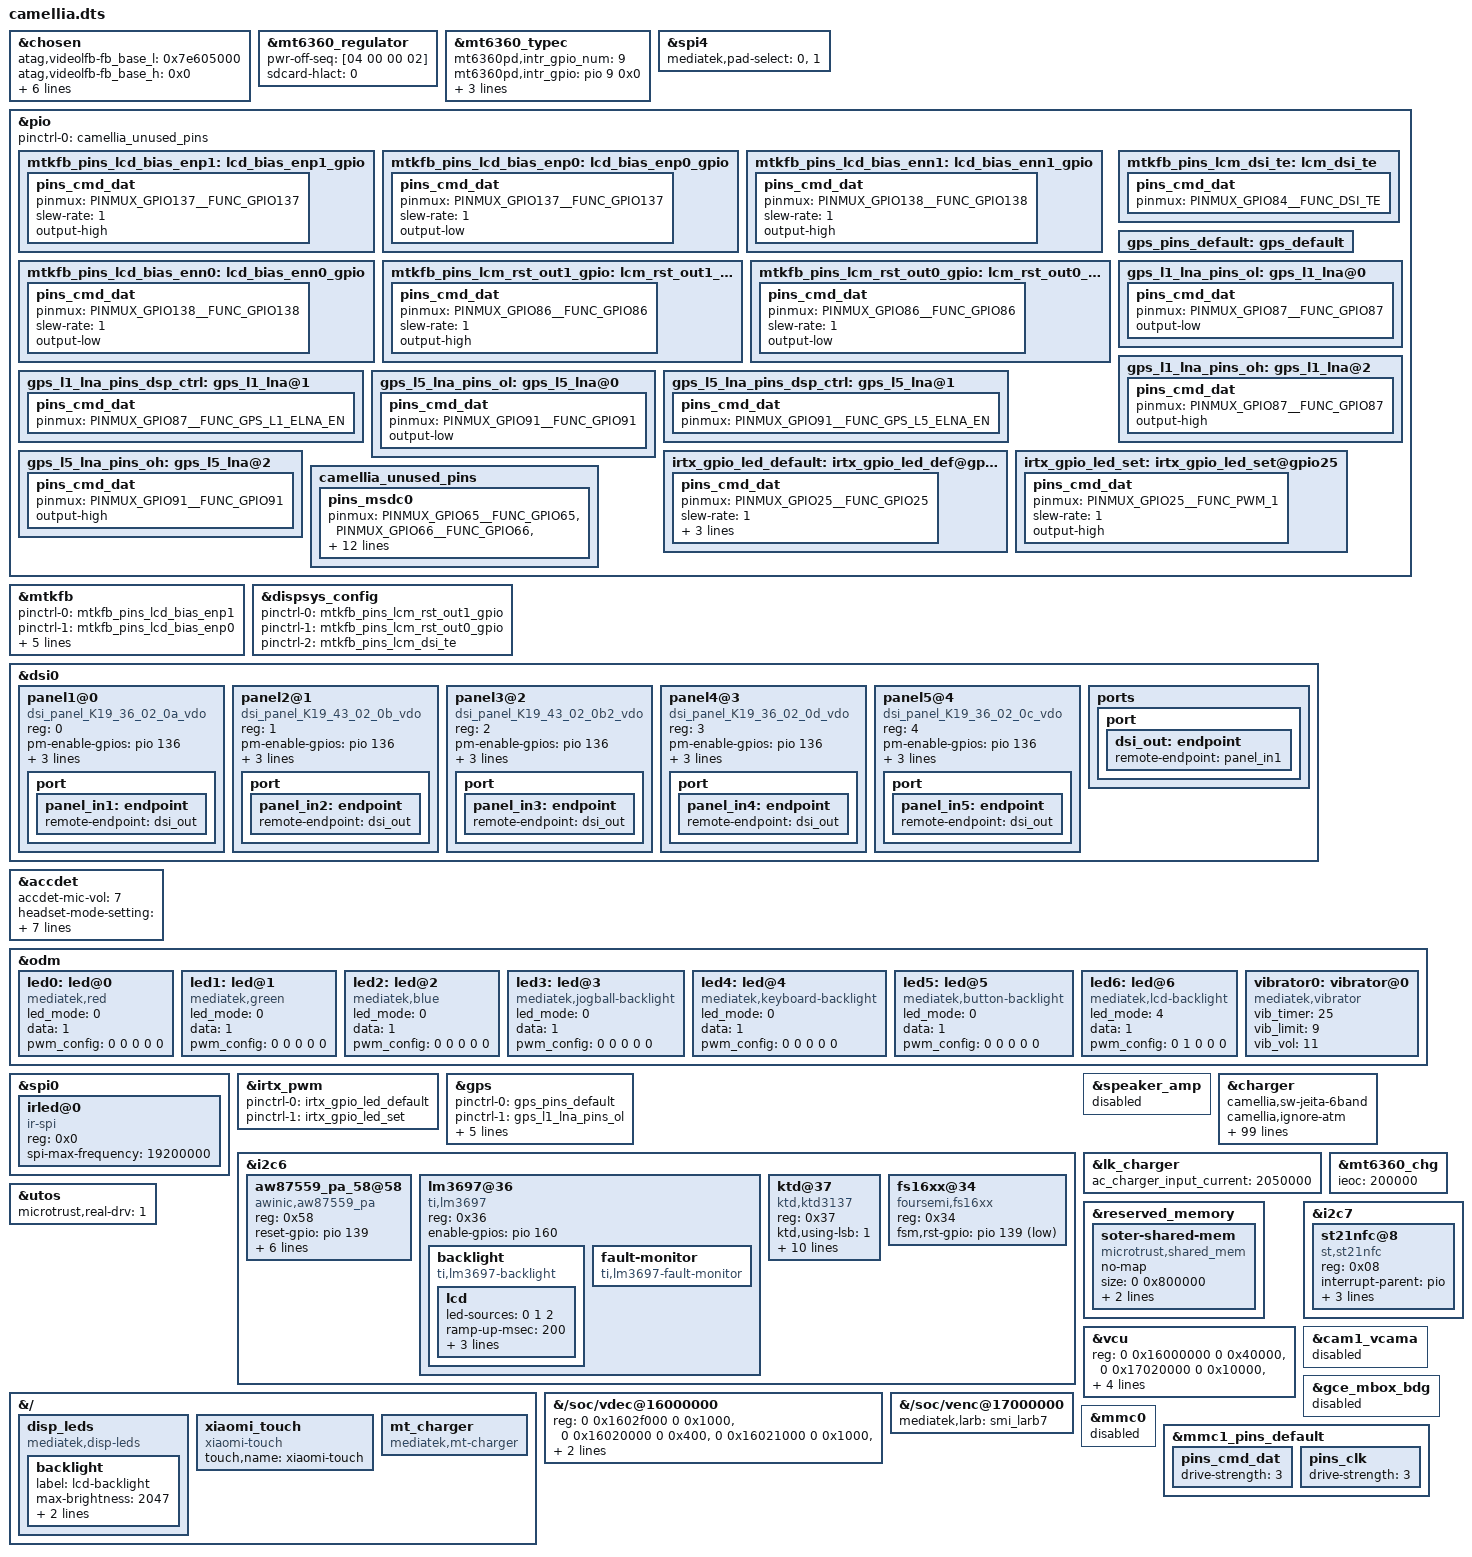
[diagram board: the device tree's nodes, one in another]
/*
 * Mediatek's mt6833 SoC device tree source
 *
 * Copyright (C) 2016 MediaTek Inc.
 *
 * This program is free software; you can redistribute it and/or modify
 * it under the terms of the GNU General Public License version 2 as
 * published by the Free Software Foundation.
 *
 * This program is distributed in the hope that it will be useful,
 * but WITHOUT ANY WARRANTY; without even the implied warranty of
 * MERCHANTABILITY or FITNESS FOR A PARTICULAR PURPOSE.
 * See http://www.gnu.org/licenses/gpl-2.0.html for more details.
 */
/dts-v1/;
/plugin/;
#include <dt-bindings/interrupt-controller/irq.h>
#include <dt-bindings/interrupt-controller/arm-gic.h>
#ifndef CONFIG_FPGA_EARLY_PORTING
#include <dt-bindings/pinctrl/mt6833-pinfunc.h>
#endif

/* chosen */
&chosen {
	atag,videolfb-fb_base_l = <0x7e605000>;
	atag,videolfb-fb_base_h = <0x0>;
	atag,videolfb-islcmfound = <1>;
	atag,videolfb-islcm_inited = <0>;
	atag,videolfb-fps= <6000>;
	atag,videolfb-vramSize= <0x1be0000>;
	atag,videolfb-lcmname=
		"nt36672c_fhdp_dsi_vdo_90hz_tianma_lcm_drv";
};

/*
 * camellia MT6360 settings in the 6.6 binding (4.14: &mt6360_ldo/_pmu/_pmic):
 * - main IRQ: GPIO10, already the 6.6 base (mt6360@34 interrupts = <&pio 10 ...>)
 * - power-off sequence [04 00 00 02]
 * - SD card detect: low level = card removed (sdcard-hlact 0; the 6.6 driver
 *   defaults to 1, which would invert microSD detection)
 */
&mt6360_regulator {
	pwr-off-seq = [04 00 00 02];
	sdcard-hlact = <0>;
};


/* BSP.Charge - 2020.11.02 - modify typec interrupt */
&mt6360_typec {
	mt6360pd,intr_gpio_num = <9>; /* direct defined GPIO num */
	mt6360pd,intr_gpio = <&pio 9 0x0>;
	/* camellia 6.6: the driver reads the dash names first, and the 6.6 base
	 * sets them to the reference board's GPIO11; camellia's TCPC IRQ is GPIO9 */
	mt6360pd,intr-gpio-num = <9>;
	mt6360pd,intr-gpio = <&pio 9 0x0>;
	/* camellia 4.14: role_def 5 (Try.SNK). The 6.6 base's Try.SRC makes a
	 * PC's DRP port see the phone as a source first, so USB device mode and
	 * BC1.2 only come up if the PC happens to swap roles back */
	mt-tcpc,role-def = <5>;
};

/* camellia 4.14: touch is NT36672C on CS0 / pad 0 or FT8722 on CS1 / pad 1
 * (by panel); spi-mt65xx gives one chip select per pad-select entry */
&spi4 {
	mediatek,pad-select = <0>, <1>;
};

#ifndef CONFIG_FPGA_EARLY_PORTING
&pio {
	mtkfb_pins_lcd_bias_enp1: lcd_bias_enp1_gpio {
		pins_cmd_dat {
			pinmux = <PINMUX_GPIO137__FUNC_GPIO137>;
			slew-rate = <1>;
			output-high;
		};
	};

	mtkfb_pins_lcd_bias_enp0: lcd_bias_enp0_gpio {
		pins_cmd_dat {
			pinmux = <PINMUX_GPIO137__FUNC_GPIO137>;
			slew-rate = <1>;
			output-low;
		};
	};

	mtkfb_pins_lcd_bias_enn1: lcd_bias_enn1_gpio {
		pins_cmd_dat {
			pinmux = <PINMUX_GPIO138__FUNC_GPIO138>;
			slew-rate = <1>;
			output-high;
		};
	};

	mtkfb_pins_lcd_bias_enn0: lcd_bias_enn0_gpio {
		pins_cmd_dat {
			pinmux = <PINMUX_GPIO138__FUNC_GPIO138>;
			slew-rate = <1>;
			output-low;
		};
	};

	mtkfb_pins_lcm_rst_out1_gpio: lcm_rst_out1_gpio {
		pins_cmd_dat {
			pinmux = <PINMUX_GPIO86__FUNC_GPIO86>;
			slew-rate = <1>;
			output-high;
		};
	};

	mtkfb_pins_lcm_rst_out0_gpio: lcm_rst_out0_gpio {
		pins_cmd_dat {
			pinmux = <PINMUX_GPIO86__FUNC_GPIO86>;
			slew-rate = <1>;
			output-low;
		};
	};
	mtkfb_pins_lcm_dsi_te: lcm_dsi_te {
		pins_cmd_dat {
			pinmux = <PINMUX_GPIO84__FUNC_DSI_TE>;
		};
	};
};

&mtkfb {
	pinctrl-names = "lcd_bias_enp1_gpio", "lcd_bias_enp0_gpio",
		"lcd_bias_enn1_gpio", "lcd_bias_enn0_gpio",
		"lcm_rst_out1_gpio", "lcm_rst_out0_gpio",
		"mode_te_te";
	pinctrl-0 = <&mtkfb_pins_lcd_bias_enp1>;
	pinctrl-1 = <&mtkfb_pins_lcd_bias_enp0>;
	pinctrl-2 = <&mtkfb_pins_lcd_bias_enn1>;
	pinctrl-3 = <&mtkfb_pins_lcd_bias_enn0>;
	pinctrl-4 = <&mtkfb_pins_lcm_rst_out1_gpio>;
	pinctrl-5 = <&mtkfb_pins_lcm_rst_out0_gpio>;
	pinctrl-6 = <&mtkfb_pins_lcm_dsi_te>;
	status = "okay";
};
&dispsys_config {
	pinctrl-names =
		"lcm_rst_out1_gpio", "lcm_rst_out0_gpio",
		"mode_te_te";
	pinctrl-0 = <&mtkfb_pins_lcm_rst_out1_gpio>;
	pinctrl-1 = <&mtkfb_pins_lcm_rst_out0_gpio>;
	pinctrl-2 = <&mtkfb_pins_lcm_dsi_te>;
	status = "okay";
};

&dsi0 {
	status = "okay";
	#address-cells = <1>;
	#size-cells = <0>;
	/* BSP.lcm - 2020.11.19 - start */
	panel1@0 {
		compatible = "dsi_panel_K19_36_02_0a_vdo";
		reg = <0>;
		pm-enable-gpios = <&pio 136 0>;
		reset-gpios = <&pio 86 0>;
		pwm-gpios = <&pio 85 0>;
		bias-gpios = <&pio 137 0>,
			<&pio 138 0>;
		pinctrl-names = "default";
		port {
			panel_in1: endpoint {
				remote-endpoint = <&dsi_out>;
			};
		};
	};
	panel2@1 {
		compatible = "dsi_panel_K19_43_02_0b_vdo";
		reg = <1>;
		pm-enable-gpios = <&pio 136 0>;
		reset-gpios = <&pio 86 0>;
		pwm-gpios = <&pio 85 0>;
		bias-gpios = <&pio 137 0>,
			<&pio 138 0>;
		pinctrl-names = "default";
		port {
			panel_in2: endpoint {
				remote-endpoint = <&dsi_out>;
			};
		};
	};
	panel3@2 {
		compatible = "dsi_panel_K19_43_02_0b2_vdo";
		reg = <2>;
		pm-enable-gpios = <&pio 136 0>;
		reset-gpios = <&pio 86 0>;
		pwm-gpios = <&pio 85 0>;
		bias-gpios = <&pio 137 0>,
			<&pio 138 0>;
		pinctrl-names = "default";
		port {
			panel_in3: endpoint {
				remote-endpoint = <&dsi_out>;
			};
		};
	};
	panel4@3 {
		compatible = "dsi_panel_K19_36_02_0d_vdo";
		reg = <3>;
		pm-enable-gpios = <&pio 136 0>;
		reset-gpios = <&pio 86 0>;
		pwm-gpios = <&pio 85 0>;
		bias-gpios = <&pio 137 0>,
			<&pio 138 0>;
		pinctrl-names = "default";
		port {
			panel_in4: endpoint {
				remote-endpoint = <&dsi_out>;
			};
		};
	};
	panel5@4 {
		compatible = "dsi_panel_K19_36_02_0c_vdo";
		reg = <4>;
		pm-enable-gpios = <&pio 136 0>;
		reset-gpios = <&pio 86 0>;
		pwm-gpios = <&pio 85 0>;
		bias-gpios = <&pio 137 0>,
			<&pio 138 0>;
		pinctrl-names = "default";
		port {
			panel_in5: endpoint {
				remote-endpoint = <&dsi_out>;
			};
		};
	};
	ports {
		port {
			dsi_out: endpoint {
				remote-endpoint = <&panel_in1>;
			};
		};
	};
};
#endif

/*BSP.Touch - Change dtsi file - 2020.11.18 - Start*/
/*#include "mediatek/cust_mt6833_touch_1080x2300.dtsi"*/
#include "mediatek/cust_mt6833_touch_1080x2400.dtsi"
/*BSP.Touch - Change dtsi file - 2020.11.18 - End*/
/* accdet start */
&accdet {
	/* accdet micbias voltage: 0x09:2.85v 0x08:2.8v 0x07,
	 * 2.7v;0x05,2.5v;0x02,1.9v
	 */
	/* BSP.audio - 2020.11.12 - modify to micbias of headphone start */
	accdet-mic-vol = <7>;
	/* BSP.audio - 2020.11.12 - modify to micbias of headphone end */
	/* accdet pwm_width, pwm_thresh, fall_delay, rise_delay
	 * debounce0, debounce1, debounce3, debounce4
	 * eint pwm_width, eint pwm_thresh
	 * eint deb(debounce0, debounce1, debounce2, debounce3), inv_debounce
	 */
	headset-mode-setting = <0x500 0x500 1 0x1f0
				0x800 0x800 0x20 0x44
				0x4 0x1
				0x5 0x3 0x3 0x5 0xe>;
	accdet-plugout-debounce = <1>;
	/*1:ACC mode, 2:low cost without in bias, 6:low cost with in bias*/
	accdet-mic-mode = <2>;
	/*0--MD_MAX--UP_MAX--DW_MAX*/
	headset-three-key-threshold = <0 80 220 400>;
	headset-three-key-threshold-CDD = <0 121 192 600>;
	/*0--MD_MAX--VOICE_MAX--UP_MAX--DW_MAX*/
	headset-four-key-threshold = <0 58 121 192 400>;

	/* select VTH to 2v and 500k, use internal resitance */
	eint_use_ext_res = <0>;
	status = "okay";
};
/* accdet end */

&odm {
	led0:led@0 {
		compatible = "mediatek,red";
		led_mode = <0>;
		data = <1>;
		pwm_config = <0 0 0 0 0>;
	};
	led1:led@1 {
		compatible = "mediatek,green";
		led_mode = <0>;
		data = <1>;
		pwm_config = <0 0 0 0 0>;
	};
	led2:led@2 {
		compatible = "mediatek,blue";
		led_mode = <0>;
		data = <1>;
		pwm_config = <0 0 0 0 0>;
	};
	led3:led@3 {
		compatible = "mediatek,jogball-backlight";
		led_mode = <0>;
		data = <1>;
		pwm_config = <0 0 0 0 0>;
	};
	led4:led@4 {
		compatible = "mediatek,keyboard-backlight";
		led_mode = <0>;
		data = <1>;
		pwm_config = <0 0 0 0 0>;
	};
	led5:led@5 {
		compatible = "mediatek,button-backlight";
		led_mode = <0>;
		data = <1>;
		pwm_config = <0 0 0 0 0>;
	};
	led6:led@6 {
		compatible = "mediatek,lcd-backlight";
		/* BSP.LCM - 2020.11.25 - modify to set brightness */
		led_mode = <4>;
		data = <1>;
		pwm_config = <0 1 0 0 0>;
	};
	vibrator0:vibrator@0 {
		compatible = "mediatek,vibrator";
		vib_timer = <25>;
		vib_limit = <9>;
	/* BSP.Charge - 2020.11.18 - Fixed the vibrator voltage */
		vib_vol= <11>;
	};
};
/* GPS GPIO standardization start */
&pio {
	gps_pins_default: gps_default {
	};

	gps_l1_lna_pins_ol: gps_l1_lna@0 {
		pins_cmd_dat {
			pinmux = <PINMUX_GPIO87__FUNC_GPIO87>;
			output-low;
		};
	};
	gps_l1_lna_pins_dsp_ctrl: gps_l1_lna@1 {
		pins_cmd_dat {
			pinmux = <PINMUX_GPIO87__FUNC_GPS_L1_ELNA_EN>;
		};
	};
	gps_l1_lna_pins_oh: gps_l1_lna@2 {
		pins_cmd_dat {
			pinmux = <PINMUX_GPIO87__FUNC_GPIO87>;
			output-high;
		};
	};

	gps_l5_lna_pins_ol: gps_l5_lna@0 {
		pins_cmd_dat {
			pinmux = <PINMUX_GPIO91__FUNC_GPIO91>;
			output-low;
		};
	};
	gps_l5_lna_pins_dsp_ctrl: gps_l5_lna@1 {
		pins_cmd_dat {
			pinmux = <PINMUX_GPIO91__FUNC_GPS_L5_ELNA_EN>;
		};
	};
	gps_l5_lna_pins_oh: gps_l5_lna@2 {
		pins_cmd_dat {
			pinmux = <PINMUX_GPIO91__FUNC_GPIO91>;
			output-high;
		};
	};
};
/*BSP.System - 2020.11.5 - add board id*/
#if 0 /* camellia 6.6 TODO: no Xiaomi board_id node/driver in 6.6 base; add node + driver */
&board_id {
	io-channels = <&auxadc 5>;
	io-channel-names = "board_id-channel";
	status = "okay";
};
#endif

&spi0 {
	status = "ok";
	irled@0 {
		compatible = "ir-spi";
		reg = <0x0>;
		//vdd-supply = <&pm8953_l8>; //vdd
		status = "ok";
		spi-max-frequency = <19200000>;
	};
};

&pio {
	/* IRTX GPIO Settings -Start */
	/* default: GPIO0, output, high */
	irtx_gpio_led_default:irtx_gpio_led_def@gpio25 {
		pins_cmd_dat {
			pinmux = <PINMUX_GPIO25__FUNC_GPIO25>;
			slew-rate = <1>;
			bias-disable;
			output-low;
			input-schmitt-enable = <0>;
		};
	};

	irtx_gpio_led_set:irtx_gpio_led_set@gpio25 {
		pins_cmd_dat {
			pinmux = <PINMUX_GPIO25__FUNC_PWM_1>;
			slew-rate = <1>;
			output-high;
		};
	};
}; /* IRTX GPIO Settings -End */

&irtx_pwm {
	pinctrl-names = "irtx_gpio_led_default", "irtx_gpio_led_set";
	pinctrl-0 = <&irtx_gpio_led_default>;
	pinctrl-1 = <&irtx_gpio_led_set>;
	status = "okay";
};

&gps {
	pinctrl-names = "default",
		"gps_l1_lna_disable",
		"gps_l1_lna_dsp_ctrl",
		"gps_l1_lna_enable",
		"gps_l5_lna_disable",
		"gps_l5_lna_dsp_ctrl",
		"gps_l5_lna_enable";
	pinctrl-0 = <&gps_pins_default>;
	pinctrl-1 = <&gps_l1_lna_pins_ol>;
	pinctrl-2 = <&gps_l1_lna_pins_dsp_ctrl>;
	pinctrl-3 = <&gps_l1_lna_pins_oh>;
	pinctrl-4 = <&gps_l5_lna_pins_ol>;
	pinctrl-5 = <&gps_l5_lna_pins_dsp_ctrl>;
	pinctrl-6 = <&gps_l5_lna_pins_oh>;
	status = "okay";
};
/* GPS GPIO standardization end */

/* BSP.Audio - 2020.11.2 - modify to bring up PA */
&i2c6 {
	aw87559_pa_58@58 {
		compatible = "awinic,aw87559_pa";
		reg = <0x58>;
		reset-gpio = <&pio 139 0>;
		monitor-flag = <1>;
		pa-channel = < 0 >;
		actflag-gain-array = < 0x00 0x08 0x08 0x08 0x00 >;
		gain-reg-addr = <0x06>;
		monitor-timer-val = <3000>;
		monitor-timer-count-max = <5>;
		status = "okay";
	};
};
/* end modify*/
/* BSP.LCM - 2020.11.14 - modify to set brightness */
&i2c6 {
	lm3697@36 {
		compatible = "ti,lm3697";
		reg = <0x36>;
		status = "okay";
		enable-gpios = <&pio 160 0>;
		backlight {
			compatible = "ti,lm3697-backlight";
			lcd {
				led-sources = <0 1 2>;
				ramp-up-msec = <200>;
				ramp-down-msec = <200>;
				pwm-period = <0>;
				default-brightness-level = <255>;
			};
		};
		fault-monitor {
			compatible = "ti,lm3697-fault-monitor";
		};
	};

	ktd@37 {
		compatible = "ktd,ktd3137";
		reg = <0x37>;
		status = "okay";
		/*ktd,pwm-mode; */
		ktd,using-lsb = <1>;
		ktd,pwm-frequency = <100>;
		ktd,bl-fscal-led = <0xA9>;/*default 21.8mA*/
		ktd,turn-on-ramp = <0>;
		ktd,turn-off-ramp = <0>;
		ktd,pwm-trans-dim = <0>;
		ktd,i2c-trans-dim = <0>;
		ktd,bl-channel = <2>;
		ktd,ovp-level = <32>; /*default 32v*/
		ktd,switching-frequency = <1000>; /*default 1000kHz*/
		ktd,inductor-current = <2600>; //default 2600mA
		//ktd,linear_ramp = <1>; /*default is exponential*/
		//ktd,linear_backlight = <1>; /*default is exponential*/
		};
};
/* end modify*/

/* camellia: the FS1815 below sits at 0x34; MTK's generic smart-PA node too */
&speaker_amp {
	status = "disabled";
};

/* BSP.Audio - 2020.11.11 - modify to bring up second PA */
&i2c6 {
	fs16xx@34 {
		compatible = "foursemi,fs16xx";
		reg = <0x34>;
		fsm,rst-gpio = <&pio 139 1>;
		status = "okay";
	};
};
/* end modify*/
#include "mediatek/cust_camellia_camera.dtsi"
#include <camellia/cust.dtsi>
#include "mediatek/cust_camellia_fingerprint.dtsi"

/*End of this file, DO NOT ADD ANYTHING HERE*/

/*
 * camellia charger settings: Xiaomi's 4.14 "mediatek,charger" node (camellian-t-oss
 * mt6833.dts). Phandle properties keep the 6.6 base values. camellia,sw-jeita-6band
 * enables Xiaomi's 6-band sw JEITA with per-band current limits (ported to 6.6).
 */
&charger {
	camellia,sw-jeita-6band;
	camellia,ignore-atm;
	/* camellia 4.14 used Xiaomi's "SwitchCharging2"; 6.6 has Basic/Pulse */
	algorithm_name = "Basic";
		/* BSP.Charge - 2020.12.02 - Eanble sw_jeita */
		enable_sw_jeita;
		/* enable_pe_plus; */
		/* enable_pe_2; */
		/* enable_pe_3; */
		/* enable_pe_4; */
		enable_type_c;
		power_path_support;
		enable_dynamic_mivr;

		/* common */
		battery_cv = <4350000>;
		/* BSP.Charge - 2021.01.11 - add ffc  parameters - start */
		enable_sw_ffc;
		ffc_cv_1 = <4440000>;
		ffc_cv_2 = <4430000>;
		ffc_cv_3 = <4420000>;
		ffc_cv_4 = <4410000>;
		chg_cycle_count_level1 = <1>;
		chg_cycle_count_level2 = <100>;
		chg_cycle_count_level3 = <200>;
		chg_cycle_count_level4 = <300>;
		/* BSP.Charge - 2021.01.11 - add ffc  parameters - end */
		max_charger_voltage = <14500000>;
		/* BSP.Charge - 2021.02.07 - lower mivr */
		min_charger_voltage = <4400000>;

		/* BSP.Charge - 2021.01.12 - add recharger  uisoc limit */
		recharger_uisoc_limit = <99>;

		/* dynamic mivr */
		min_charger_voltage_1 = <4200000>;
		min_charger_voltage_2 = <4000000>;
		max_dmivr_charger_current = <1400000>;

		/* charging current */
		usb_charger_current_suspend = <0>;
		usb_charger_current_unconfigured = <70000>;
		usb_charger_current_configured = <500000>;
		usb_charger_current = <500000>;
		ac_charger_current = <2050000>;
		ac_charger_input_current = <2050000>;
		/*BSP.Charge - 2020.11.18 - The charging current of non-standard charger is adjusted to 1A - start*/
		non_std_ac_charger_current = <1000000>;
		/*BSP.Charge - 2020.11.18 - The charging current of non-standard charger is adjusted to 1A - end*/
		charging_host_charger_current = <1500000>;
		apple_1_0a_charger_current = <650000>;
		apple_2_1a_charger_current = <800000>;
		ta_ac_charger_current = <3000000>;

		/* sw jeita */
		/* BSP.Charge - 2020.12.02 - modify sw_jeita standard - start */
		jeita_temp_above_t4_cv = <4090000>;
		jeita_temp_t3_to_t4_cv = <4440000>;
		jeita_temp_t2_to_t3_cv = <4440000>;
		jeita_temp_t1_to_t2_cv = <4440000>;
		jeita_temp_t0_to_t1_cv = <4440000>;
		jeita_temp_below_t0_cv = <4440000>;

		jeita_temp_t4_to_t5_cc = <2450000>;
		/* BSP.Charge - 2020.12.17 - modify sw_jeita standard - start */
		jeita_temp_t3_to_t4_cc = <3200000>;
		jeita_temp_t2_to_t3_cc = <3200000>;
		jeita_temp_t1_to_t2_cc = <2450000>;
		/* BSP.Charge - 2020.12.17 - modify sw_jeita standard - end */
		jeita_temp_t0_to_t1_cc = <980000>;
		jeita_temp_below_t0_cc = <490000>;

		temp_t5_thres = <58>;
		temp_t5_thres_minus_x_degree = <55>;
		temp_t4_thres = <48>;
		temp_t4_thres_minus_x_degree = <45>;
		temp_t3_thres = <15>;
		temp_t3_thres_plus_x_degree = <23>;
		temp_t2_thres = <10>;
		temp_t2_thres_plus_x_degree = <10>;
		temp_t1_thres = <5>;
		temp_t1_thres_plus_x_degree = <5>;
		temp_t0_thres = <0>;
		temp_t0_thres_plus_x_degree = <0>;
		temp_neg_10_thres = <10>;

		/* battery temperature protection */
		enable_min_charge_temp;
		min_charge_temp = <10>;
		min_charge_temp_plus_x_degree = <0>;
		max_charge_temp = <58>;
		max_charge_temp_minus_x_degree = <56>;
		/* BSP.Charge - 2020.12.02 - modify sw_jeita standard - end */
		/* PE */
		ta_12v_support;
		ta_9v_support;
		pe_ichg_level_threshold = <1000000>; /* uA */
		ta_ac_12v_input_current = <3200000>;
		ta_ac_9v_input_current = <3200000>;
		ta_ac_7v_input_current = <3200000>;

		/* PE 2.0 */
		pe20_ichg_level_threshold = <1000000>; /* uA */
		ta_start_battery_soc = <0>;
		ta_stop_battery_soc = <85>;

		/* PE 4.0 */
		high_temp_to_leave_pe40 = <46>;
		high_temp_to_enter_pe40 = <39>;
		low_temp_to_leave_pe40 = <10>;
		low_temp_to_enter_pe40 = <16>;

		/* PE 4.0 single charger*/
		pe40_single_charger_input_current = <3000000>;
		pe40_single_charger_current = <3000000>;

		/* PE 4.0 dual charger*/
		pe40_dual_charger_input_current = <3000000>;
		pe40_dual_charger_chg1_current = <2000000>;
		pe40_dual_charger_chg2_current = <2000000>;
		pe40_stop_battery_soc = <80>;

		/* PE 4.0 cable impedance (mohm) */
		pe40_r_cable_1a_lower = <559>;
		pe40_r_cable_2a_lower = <420>;
		pe40_r_cable_3a_lower = <279>;

		/* dual charger */
		chg1_ta_ac_charger_current = <1500000>;
		chg2_ta_ac_charger_current = <1500000>;
		slave_mivr_diff = <100000>;
		dual_polling_ieoc = <750000>;

		/* cable measurement impedance */
		cable_imp_threshold = <699>;
		vbat_cable_imp_threshold = <3900000>; /* uV */

		/* bif */
		bif_threshold1 = <4250000>;
		bif_threshold2 = <4300000>;
		bif_cv_under_threshold2 = <4450000>;

		/* PD */
		pd_vbus_low_bound = <5000000>;
		pd_vbus_upper_bound = <5000000>;
		pd_ichg_level_threshold = <1000000>; /* uA */
		pd_stop_battery_soc = <80>;

		ibus_err = <14>;
		vsys_watt = <5000000>;
};

/*
 * camellia backlight: the 6.6 base mtk_leds node has no compatible (Camellia sets
 * it per board), so leds-mtk-disp would never bind. camellia 4.14 used
 * mediatek,disp-leds with an 11-bit backlight (BSP.LCM 2020.12.16: 2047).
 * leds-mtk-disp also drives the KTD3136/LM3697 IC LK reports in ":bklic=".
 */
/*
 * Charger limits as in camellia's stock dt. LK reads lk_charger for off-mode
 * charging: the mt6833 default lets it draw 3.2 A from a DCP (stock 2.05 A).
 * max_charger_voltage (6.5 V) and non_std (0.5 A) stay below stock's 14.5 V/1 A.
 */
&lk_charger {
	ac_charger_input_current = <2050000>;
};

&mt6360_chg {
	ieoc = <200000>;	/* stock end-of-charge current (6.6 default 150 mA) */
};

/*
 * Microtrust TEE (Beanpod keymaster, teei_daemon). The 6.6 isee driver only
 * starts uTos when the board marks it real ("MICROTRUST device is NOT enable"
 * otherwise; Camellia boards set the trustonic equivalent per project).
 */
&utos {
	microtrust,real-drv = <1>;
};

/* TEE shared memory, as in camellia's stock dt (soter, isee TEEI_DTS_RESERVED_MEM) */
&reserved_memory {
	soter-shared-mem {
		compatible = "microtrust,shared_mem";
		no-map;
		size = <0 0x800000>;
		alignment = <0 0x1000000>;
		alloc-ranges = <0 0x40000000 0 0x50000000>;
	};
};

/*
 * A new root node rather than &mtk_leds: the stock sepolicy labels the
 * backlight sysfs_leds by path, /sys/devices/platform/disp_leds/leds/...
 * (4.14's node name). Under mtk_leds it stays plain sysfs, and the
 * framework, lights HAL and displayfeature cannot write it.
 */
&{/} {
	disp_leds {
		compatible = "mediatek,disp-leds";

		backlight {
			label = "lcd-backlight";
			max-brightness = <2047>;
			max-hw-brightness = <2047>;
			default-state = "on";
		};
	};
};

/* camellia 4.14 base dtb: platform device for the xiaomi-touch mode/feature
 * glue (touchfeature HAL); FT8722/NT36672C register into it at probe */
&{/} {
	xiaomi_touch {
		compatible = "xiaomi-touch";
		status = "okay";
		touch,name = "xiaomi-touch";
	};

	/* 4.14 "ac"/"usb" supplies at /sys/devices/platform/mt_charger, the path
	 * the stock vendor sepolicy labels sysfs_batteryinfo (camellia_mt_charger) */
	mt_charger {
		compatible = "mediatek,mt-charger";
	};
};

/*
 * camellia: video codec nodes in the layout of the 4.14 driver the stock
 * vpud/codec2 need (camellia_vcodec): stock reg order and VCU GCE threads,
 * "mediatek,larb" and the 4.14 clock names, on the 6.6 clock/IOMMU providers.
 */
&vcu {
	reg = <0 0x16000000 0 0x40000>,	/* VDEC_BASE */
	      <0 0x17020000 0 0x10000>,	/* VENC_BASE */
	      <0 0x17820000 0 0x10000>;	/* VENC_C1_BASE (stock) */
	mediatek,dec_gce_th_num = <1>;
	mediatek,enc_gce_th_num = <1>;
	/* dec thread, enc thread, secure enc thread (stock order) */
	mboxes = <&gce 7 0 1>, <&gce 12 0 1>, <&gce_sec 12 0 1>;
};

&{/soc/vdec@16000000} {
	reg = <0 0x1602f000 0 0x1000>,	/* VDEC_SYS */
	      <0 0x16020000 0 0x400>,	/* VDEC_VLD */
	      <0 0x16021000 0 0x1000>,	/* VDEC_MC */
	      <0 0x16023000 0 0x1000>,	/* VDEC_MV */
	      <0 0x16025000 0 0x1000>;	/* VDEC_MISC */
	/delete-property/ reg-names;
	mediatek,larb = <&smi_larb4>;
	clock-names = "MT_CG_VDEC";
};

&{/soc/venc@17000000} {
	mediatek,larb = <&smi_larb7>;
	clock-names = "MT_CG_VENC";
};

/* ST21NFC on i2c7 @0x08: IRQ GPIO5, reset GPIO48 (4.14 cust.dtsi + mt6833.dts nfc node) */
&i2c7 {
	st21nfc@8 {
		compatible = "st,st21nfc";
		reg = <0x08>;
		interrupt-parent = <&pio>;
		interrupts = <5 IRQ_TYPE_LEVEL_HIGH>;
		irq-gpios = <&pio 5 0>;
		reset-gpios = <&pio 48 0>;
		status = "okay";
	};
};

/* MediaTek reference board's vcama GPIO regulator: on camellia GPIO92 is unused
 * (cam1 vcama is GPIO7), stock leaves it an input */
&cam1_vcama {
	status = "disabled";
};

/* No MT6382 display bridge on camellia: nothing binds this mailbox, and as an
 * fw_devlink supplier it held off mediatek-drm until the deferred probe timeout
 * (~40s), after the composer HAL had already started and crashed.
 */
&gce_mbox_bdg {
	status = "disabled";
};

/* camellia boots from UFS, there is no eMMC: the reference-board mmc0 only
 * probed and reset an empty bus. Park its pins pulled down, as stock does.
 */
&mmc0 {
	status = "disabled";
};

&pio {
	pinctrl-names = "default";
	pinctrl-0 = <&camellia_unused_pins>;

	camellia_unused_pins: camellia_unused_pins {
		pins_msdc0 {
			pinmux = <PINMUX_GPIO65__FUNC_GPIO65>,
				 <PINMUX_GPIO66__FUNC_GPIO66>,
				 <PINMUX_GPIO67__FUNC_GPIO67>,
				 <PINMUX_GPIO68__FUNC_GPIO68>,
				 <PINMUX_GPIO69__FUNC_GPIO69>,
				 <PINMUX_GPIO70__FUNC_GPIO70>,
				 <PINMUX_GPIO71__FUNC_GPIO71>,
				 <PINMUX_GPIO72__FUNC_GPIO72>,
				 <PINMUX_GPIO73__FUNC_GPIO73>,
				 <PINMUX_GPIO74__FUNC_GPIO74>,
				 <PINMUX_GPIO75__FUNC_GPIO75>,
				 <PINMUX_GPIO76__FUNC_GPIO76>;
			input-enable;
			bias-pull-down;
		};
	};
};

/* microSD: idle drive strength as on 4.14 (the UHS state already uses 3) */
&mmc1_pins_default {
	pins_cmd_dat {
		drive-strength = <3>;
	};
	pins_clk {
		drive-strength = <3>;
	};
};
